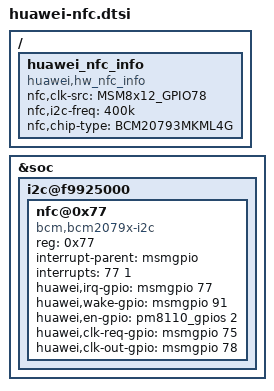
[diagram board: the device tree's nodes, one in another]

 / {
        huawei_nfc_info {
                  compatible = "huawei,hw_nfc_info";
	           nfc,clk-src = "MSM8x12_GPIO78";
	           nfc,i2c-freq = "400k";
		    nfc,chip-type = "BCM20793MKML4G";
                  status = "ok";
        };
};


&soc {
	i2c@f9925000 { /* BLSP1 QUP3 */
	    nfc@0x77 {
	       compatible = "bcm,bcm2079x-i2c";
		status = "ok";
		reg = <0x77>;
              interrupt-parent = <&msmgpio>;
		interrupts = <77 1>; /*1 = low-to-high edge triggered
     		                                 2 = high-to-low edge triggered
     		                                 4 = active high level-sensitive
     		                                 8 = active low level-sensitive */
		
		huawei,irq-gpio = <&msmgpio 77 0>;
		huawei,wake-gpio = <&msmgpio 91 0>;
		huawei,en-gpio = <&pm8110_gpios 2 0>;
		huawei,clk-req-gpio = <&msmgpio 75 0>;	
		huawei,clk-out-gpio = <&msmgpio 78 0>;	
	    };
	};
};
        	
